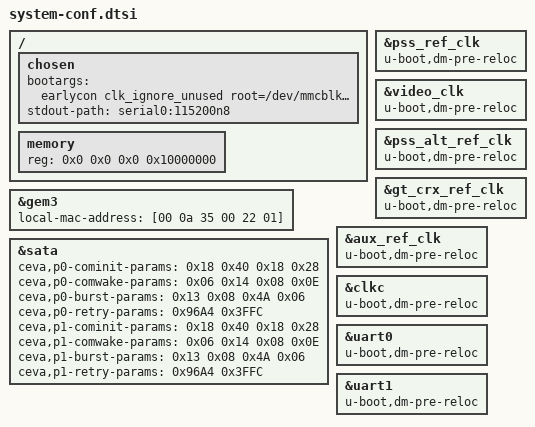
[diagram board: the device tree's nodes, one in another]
/*
 * CAUTION: This file is automatically generated by PetaLinux SDK.
 * DO NOT modify this file
 */


/ {
	chosen {
		bootargs = "earlycon clk_ignore_unused root=/dev/mmcblk0p2 rw rootwait";
		stdout-path = "serial0:115200n8";
	};
	memory {
		device_type = "memory";
		reg = <0x0 0x0 0x0 0x10000000>;
	};
};

&gem3 {
	local-mac-address = [00 0a 35 00 22 01];
};


&sata {


	ceva,p0-cominit-params = /bits/ 8 <0x18 0x40 0x18 0x28>;
	ceva,p0-comwake-params = /bits/ 8 <0x06 0x14 0x08 0x0E>;
	ceva,p0-burst-params = /bits/ 8 <0x13 0x08 0x4A 0x06>;
	ceva,p0-retry-params = /bits/ 16 <0x96A4 0x3FFC>;

	ceva,p1-cominit-params = /bits/ 8 <0x18 0x40 0x18 0x28>;
	ceva,p1-comwake-params = /bits/ 8 <0x06 0x14 0x08 0x0E>;
	ceva,p1-burst-params = /bits/ 8 <0x13 0x08 0x4A 0x06>;
	ceva,p1-retry-params = /bits/ 16 <0x96A4 0x3FFC>;

};

&pss_ref_clk {
	u-boot,dm-pre-reloc;
};


&video_clk {
	u-boot,dm-pre-reloc;
};


&pss_alt_ref_clk {
	u-boot,dm-pre-reloc;
};


&gt_crx_ref_clk {
	u-boot,dm-pre-reloc;
};


&aux_ref_clk {
	u-boot,dm-pre-reloc;
};


&clkc {
	u-boot,dm-pre-reloc;
};


&uart0 {

	u-boot,dm-pre-reloc;
};


&uart1 {

	u-boot,dm-pre-reloc;
};

